# ADSP-SC83xW_HPC register map
Vendor: Analog Devices; Series: ADSP-SC83xW_HPC; File version: 3.0.3.517
CPU: 
Registers are 32-bit, read-write, reset 0x0 unless marked. A register's access mark holds for its fields unless they carry their own. Offsets are from the block's base; [hi:lo] are bit positions; {n}, {i} and the like mark numbered series; 'fields as' and 'values as' point back to an identical list.

## DMC0 — Dynamic Memory Controller
Base 0x31070000
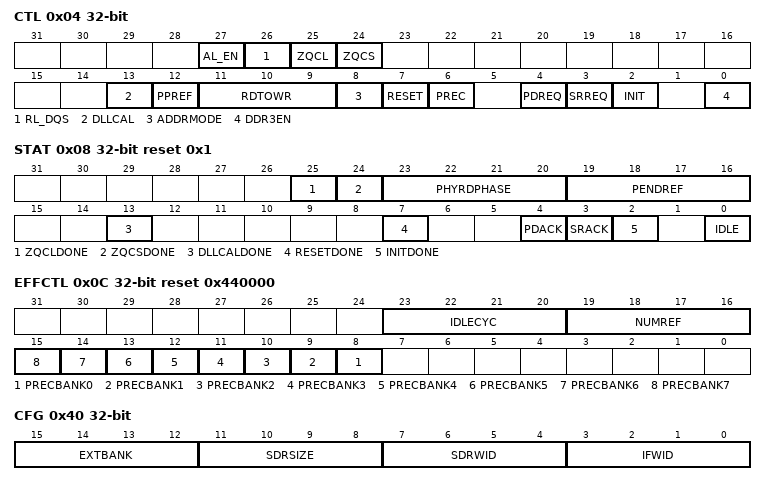
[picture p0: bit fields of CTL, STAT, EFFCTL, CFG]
0x04 CTL — Control Register
  [27] AL_EN
    0=DISGT667MHZ (Disables greater than 667MHz operation); 1=ENGT667MHZ (Enables greater than 667MHz operation)
  [26] RL_DQS
  [25] ZQCL — ZQ Calibration Long
  [24] ZQCS — ZQ Calibration Short
  [13] DLLCAL — DLL Calibration Start
  [12] PPREF — Postpone Refresh
  [11:9] RDTOWR — Read-to-Write Cycle
    0=1 Cycle Added from JEDEC Spec Value; {v}={v+1} Cycles Added from JEDEC Spec Value (v=1..7)
  [8] ADDRMODE — Addressing (Page/Bank) Mode
  [7] RESET — Reset SDRAM
  [6] PREC — Precharge
  [4] PDREQ — Power Down Request
  [3] SRREQ — Self-Refresh Request
  [2] INIT — Initialize DRAM Start
  [0] DDR3EN — DDR3 Mode
    1=DDR3MODE (Enable DDR3 mode)
0x08 STAT reset 0x1 — Status Register
  [25] ZQCLDONE ro — ZQ Calibration Long Done
  [24] ZQCSDONE ro — ZQ Calibration Short Done
  [23:20] PHYRDPHASE ro — PHY Read Phase
  [19:16] PENDREF ro — Pending Refresh
  [13] DLLCALDONE ro — DLL Calibration Done
  [7] RESETDONE ro
  [4] PDACK ro — Power-Down Acknowledge
  [3] SRACK ro — Self-Refresh Acknowledge
  [2] INITDONE ro — Initialization Done
  [0] IDLE ro — Idle State
0x0C EFFCTL reset 0x440000 — Efficiency Control Register
  [23:20] IDLECYC — Idle Cycle
  [19:16] NUMREF — Number of Refresh Commands
  [n+8] PRECBANK{n} (n=0..7) — Precharge Bank {n}
0x10 PRIO — Priority ID Register 1
  [31:0] ID1 range 0x00000000..0xFFFFFFFF — SCB ID1 that Requires Elevated Priority
0x14 PRIOMSK — Priority ID Mask Register 1
  [31:0] ID1MSK range 0x00000000..0xFFFFFFFF — Mask for SCB ID1
0x18 PRIO2 — Priority ID Register 2
  [31:0] ID2 range 0x00000000..0xFFFFFFFF — SCB ID2 that Requires Elevated Priority
0x1C PRIOMSK2 — Priority ID Mask Register 2
  [31:0] ID2MSK range 0x00000000..0xFFFFFFFF — Mask for SCB ID2
0x40 CFG — Configuration Register
  [15:12] EXTBANK — External Banks
    0=1 External Bank
  [11:8] SDRSIZE — SDRAM Size
    3=512M Bit SDRAM; 4=SDRSIZE1G (1G Bit SDRAM); 5=SDRSIZE2G (2G Bit SDRAM); 6=SDRSIZE4G (4G Bit SDRAM); 7=SDRSIZE8G (8G Bit SDRAM)
  [7:4] SDRWID — SDRAM Width
  [3:0] IFWID — Interface Width
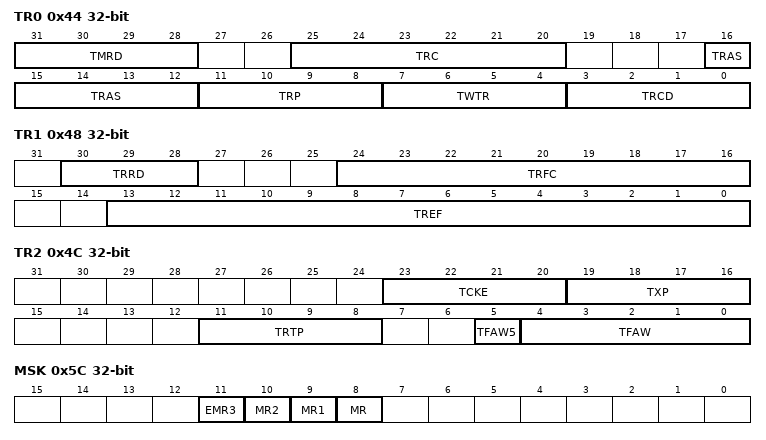
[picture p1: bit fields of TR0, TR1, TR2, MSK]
0x44 TR0 — Timing 0 Register
  [31:28] TMRD range 0x00000000..0x0000000F — Timing Mode Register Delay
  [25:20] TRC range 0x00000000..0x0000003F — Timing Row Cycle
  [16:12] TRAS range 0x00000000..0x0000001F — Timing Row Active Time
  [11:8] TRP range 0x00000000..0x0000000F — Timing RAS Precharge
  [7:4] TWTR range 0x00000000..0x0000000F — Timing Write to Read
  [3:0] TRCD range 0x00000000..0x0000000F — Timing RAS to CAS Delay
0x48 TR1 — Timing 1 Register
  [30:28] TRRD range 0x00000000..0x00000007 — Timing Read-Read Delay
  [24:16] TRFC range 0x00000000..0x000001FF — Timing Refresh-to-Command
  [13:0] TREF range 0x00000000..0x00003FFF — Timing Refresh Interval
0x4C TR2 — Timing 2 Register
  [23:20] TCKE range 0x00000000..0x0000000F — Timing Clock Enable
  [19:16] TXP range 0x00000000..0x0000000F — Timing Exit Power Down
  [11:8] TRTP range 0x00000000..0x0000000F — Timing Read-to-Precharge
  [5] TFAW5 wo range 0x00000000..0x00000001 — Extended Timing Four-Active Window Bit 5
  [4:0] TFAW range 0x00000000..0x0000001F — Timing Four-Activated-Window
0x5C MSK — Mask (Mode Register Shadow) Register
  [11] EMR3 — Shadow EMR3 Unmask
  [10] MR2 — Shadow MR2 Unmask
  [9] MR1 — Shadow MR1 Unmask
  [8] MR — Shadow MR Unmask
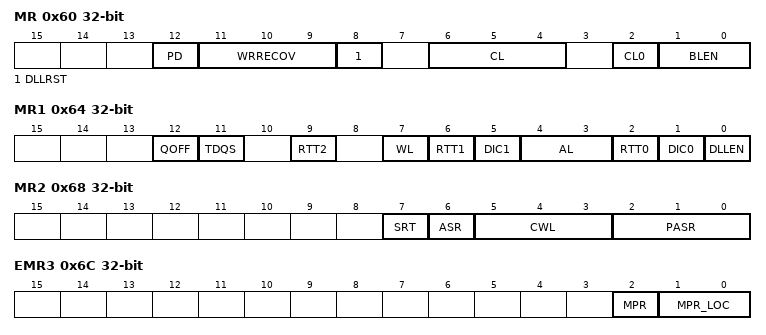
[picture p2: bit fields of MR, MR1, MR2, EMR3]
0x60 MR — Shadow MR0 Register (DDR3)
  [12] PD — Active Power Down Mode
  [11:9] WRRECOV — Write Recovery
  [8] DLLRST — DLL Reset
  [6:4] CL range 0x00000000..0x00000007 — CAS Latency
  [2] CL0 range 0x00000000..0x00000001 — CAS Latency 0
  [1:0] BLEN — Burst Length
    0=BLEN8_DDR3 (8-Bit Burst Length - DDR3 only)
0x64 MR1 — Shadow MR1 Register (DDR3)
  [12] QOFF — Output Buffer Enable
  [11] TDQS — Termination Data Strobe
  [9] RTT2 range 0x00000000..0x00000001 — Rtt_nom
  [7] WL — Write Leveling Enable
  [6] RTT1 range 0x00000000..0x00000001 — Rtt_nom
  [5] DIC1 range 0x00000000..0x00000001 — Output Driver Impedance Control
  [4:3] AL — Additive Latency
  [2] RTT0 range 0x00000000..0x00000001 — Rtt_nom
  [1] DIC0 range 0x00000000..0x00000001 — Output Driver Impedance control
  [0] DLLEN — DLL Enable
0x68 MR2 — Shadow MR2 Register (DDR3)
  [7] SRT — Self Refresh Temperature Range
  [6] ASR — Auto Self Refresh
    0=SRT (Manual SR Reference (SRT)); 1=ASREN (ASR enable (Optional))
  [5:3] CWL — CAS Write Latency
  [2:0] PASR — Partial Array Self refresh
0x6C EMR3 — Shadow EMR3 Register
  [2] MPR — Multi Purpose Read Enable (Read Leveling)
  [1:0] MPR_LOC ro — Hardcoded to "00". Reads a pre-defined pattern on MPR read.
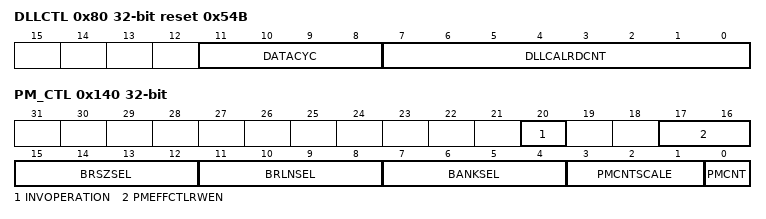
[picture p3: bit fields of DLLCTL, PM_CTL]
0x80 DLLCTL reset 0x54B — DLL Control Register
  [11:8] DATACYC — Data Cycles
    {v}={v} Clock Cycles Latency (v=2..15)
  [7:0] DLLCALRDCNT range 0x00000000..0x000000FF — DLL Calibration RD Count
0x90 DT_CALIB_ADDR — Data Calibration Address Register
  [31:0] DMC_DT_CALIB_ADDR range 0x00000000..0xFFFFFFFF — Data calibration address
0x94 DT_DATA_CALIB_DATA0 — Data Calibration Data 0 Register
  [31:0] DMC_DT_DATA_CALIB_DATA0 range 0x00000000..0xFFFFFFFF — Data Calibration Data 0
0x98 DT_DATA_CALIB_DATA1 reset 0xFFFFFFFF — Data Calibration Data 1 Register
  [31:0] DMC_DT_DATA_CALIB_DATA1 range 0x00000000..0xFFFFFFFF — Data Calibration Data 1
0x100 RDDATABUFID1 — DMC Read Data Buffer ID Register 1
  [31:0] VALUE range 0x00000000..0xFFFFFFFF — Mask for Read Data Buffer ID1
0x104 RDDATABUFMSK1 — DMC Read Data Buffer Mask Register 1
  fields as RDDATABUFID1
0x108 RDDATABUFID2 — DMC Read Data Buffer ID Register 2
  [31:0] VALUE range 0x00000000..0xFFFFFFFF — Mask for Read Data Buffer ID2
0x10C RDDATABUFMSK2 — DMC Read Data Buffer Mask Register 2
  fields as RDDATABUFID2
0x140 PM_CTL — DMC Performance Control Register
  [20] INVOPERATION — Inverted Operation
  [17:16] PMEFFCTLRWEN — Performance Monitor Read/Write Select
  [15:12] BRSZSEL — Burst Size Select
  [11:8] BRLNSEL — Burst Length Select
  [7:4] BANKSEL — Bank Select
  [3:1] PMCNTSCALE — Performance Monitor Scale
  [0] PMCNT — Performance Monitor Control
0x144 PM_IDPG_CNT — Performance Monitor Idle Page Count Register
  [31:0] VALUE ro — Idle page access count
0x148 PM_PGMS_CNT — Performance Monitor Page Miss Count
  [31:0] VALUE ro — Page miss count
0x14C PM_PGHT_CNT — Performance Monitor Page Hit Count
  [31:0] VALUE ro — Page hit count
0x150 PM_IDCYDQ_CNT — Performance Monitor Idle Cycle DQ Count Register
  [31:0] VALUE ro — Idle cycles count
0x154 PM_RD2WRTA_CNT — Performance Monitor Read to Write Turn Around Count Register
  [31:0] VALUE ro — Read to write turn around count
0x158 PM_WR2RDTA_CNT — Performance Monitor Write to Read Turn Around Count Register
  [31:0] VALUE ro — Write to read turn around count
0x15C PM_REF_CNT — Performance Monitor Refresh Count Register
  [31:0] VALUE ro — Refresh count
0x164 SCB_PM_IDWRDCY_CNT — SCB Performance Monitor Idle Cycle Count Register
  [31:0] VALUE ro — Write Idle Cycle Count
0x168 SCB_PM_IDRDDCY_CNT — SCB Performance Monitor Idle Cycle Count Register
  [31:0] VALUE ro — Read Idle Cycle Count
0x174 RDD_BUFHT_CNT — Performance Monitor Buffer Hit Count Register
  [31:0] VALUE ro — Buffer Hit Count
0x178 SCB_PM_BRLN_CNT — SCB Performance AXI Transfer Count Register
  [31:0] VALUE ro — Burst Length Transfer Count
0x17C SCB_PM_BRSZ_CNT — SCB Performance AXI Transfer Count Register
  [31:0] VALUE ro — Burst Size Transfer Count
